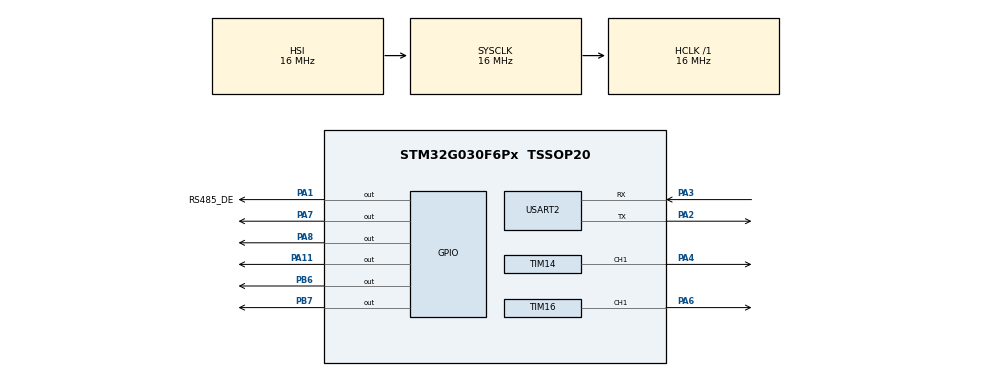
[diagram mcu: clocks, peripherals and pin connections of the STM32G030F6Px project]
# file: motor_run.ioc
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Mcu.Family=STM32G0
Mcu.Name=STM32G030F6Px
Mcu.Package=TSSOP20
PA1.GPIO_Label=RS485_DE
PA1.Signal=GPIO_Output
PA11\ [PA9].Signal=GPIO_Output
PA13.Mode=Serial_Wire
PA13.Signal=SYS_SWDIO
PA14-BOOT0.Mode=Serial_Wire
PA14-BOOT0.Signal=SYS_SWCLK
PA14-BOOT0__PA15.StandardMode=true
PA2.Mode=Asynchronous
PA2.Signal=USART2_TX
PA3.Mode=Asynchronous
PA3.Signal=USART2_RX
PA4.Signal=S_TIM14_CH1
PA6.Signal=S_TIM16_CH1
PA7.Signal=GPIO_Output
PA8.Signal=GPIO_Output
PB0__PB1__PB2__PA8.StandardMode=true
PB3__PB4__PB5__PB6.StandardMode=true
PB6.Signal=GPIO_Output
PB7.Signal=GPIO_Output
PB7__PB8.StandardMode=true
PC14-OSC32_IN\ (PC14)__PB9.StandardMode=true
ProjectManager.HeapSize=0x200
ProjectManager.StackSize=0x400
ProjectManager.TargetToolchain=MDK-ARM V5.32
RCC.AHBFreq_Value=16000000
RCC.CortexFreq_Value=16000000
RCC.EXTERNAL_CLOCK_VALUE=12288000
RCC.HCLKFreq_Value=16000000
RCC.HSE_VALUE=8000000
RCC.HSI_VALUE=16000000
RCC.LSE_VALUE=32768
RCC.SYSCLKFreq_VALUE=16000000
RCC.VCOOutputFreq_Value=128000000
SH.S_TIM14_CH1.0=TIM14_CH1,PWM Generation1 CH1
SH.S_TIM16_CH1.0=TIM16_CH1,PWM Generation1 CH1
TIM14.Channel=TIM_CHANNEL_1
TIM14.Period=19999
TIM14.Prescaler=15
TIM14.Pulse=1500
TIM16.Channel=TIM_CHANNEL_1
TIM16.Period=19999
TIM16.Prescaler=15
TIM16.Pulse=1500
USART2.VirtualMode-Asynchronous=VM_ASYNC
VP_TIM14_VS_ClockSourceINT.Mode=Enable_Timer
VP_TIM16_VS_ClockSourceINT.Mode=Enable_Timer
board=custom

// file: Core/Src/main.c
/* USER CODE BEGIN Header */
/**
  ******************************************************************************
  * @file           : main.c
  * @brief          : Main program body
  ******************************************************************************
  * @attention
  *
  * Copyright (c) 2026 STMicroelectronics.
  * All rights reserved.
  *
  * This software is licensed under terms that can be found in the LICENSE file
  * in the root directory of this software component.
  * If no LICENSE file comes with this software, it is provided AS-IS.
  *
  ******************************************************************************
  */
/* USER CODE END Header */
#include "main.h"
#include "tim.h"
#include "usart.h"
#include "gpio.h"

/* USER CODE BEGIN Includes */
#include "motor_pwm.h"
#include "d03_rs485.h"
/* USER CODE END Includes */

void SystemClock_Config(void);

int main(void)
{

  /* MCU Configuration--------------------------------------------------------*/

  /* Reset of all peripherals, Initializes the Flash interface and the Systick. */
  HAL_Init();

  /* Configure the system clock */
  SystemClock_Config();

  /* Initialize all configured peripherals */
  MX_GPIO_Init();
  MX_TIM14_Init();
  MX_TIM16_Init();
  MX_USART2_UART_Init();
  /* USER CODE BEGIN 2 */
  Motor_Init();
  D03_RS485_Init();
  /* 上电不打中位：无 PWM 脉宽，等 RS485 速度帧再动 */
  /* USER CODE END 2 */

  /* Infinite loop */
  while (1)
  {

    /* USER CODE BEGIN 3 */
    D03_RS485_Poll();
  }
  /* USER CODE END 3 */
}

void SystemClock_Config(void)
{
  RCC_OscInitTypeDef RCC_OscInitStruct = {0};
  RCC_ClkInitTypeDef RCC_ClkInitStruct = {0};

  /** Configure the main internal regulator output voltage
  */
  HAL_PWREx_ControlVoltageScaling(PWR_REGULATOR_VOLTAGE_SCALE1);

  /** Initializes the RCC Oscillators according to the specified parameters
  * in the RCC_OscInitTypeDef structure.
  */
  RCC_OscInitStruct.OscillatorType = RCC_OSCILLATORTYPE_HSI;
  RCC_OscInitStruct.HSIState = RCC_HSI_ON;
  RCC_OscInitStruct.HSIDiv = RCC_HSI_DIV1;
  RCC_OscInitStruct.HSICalibrationValue = RCC_HSICALIBRATION_DEFAULT;
  RCC_OscInitStruct.PLL.PLLState = RCC_PLL_NONE;
  if (HAL_RCC_OscConfig(&RCC_OscInitStruct) != HAL_OK)
  {
    Error_Handler();
  }

  /** Initializes the CPU, AHB and APB buses clocks
  */
  RCC_ClkInitStruct.ClockType = RCC_CLOCKTYPE_HCLK|RCC_CLOCKTYPE_SYSCLK
                              |RCC_CLOCKTYPE_PCLK1;
  RCC_ClkInitStruct.SYSCLKSource = RCC_SYSCLKSOURCE_HSI;
  RCC_ClkInitStruct.AHBCLKDivider = RCC_SYSCLK_DIV1;
  RCC_ClkInitStruct.APB1CLKDivider = RCC_HCLK_DIV1;

  if (HAL_RCC_ClockConfig(&RCC_ClkInitStruct, FLASH_LATENCY_0) != HAL_OK)
  {
    Error_Handler();
  }
}

void Error_Handler(void)
{
  __disable_irq();
  while (1)
  {
  }
}
